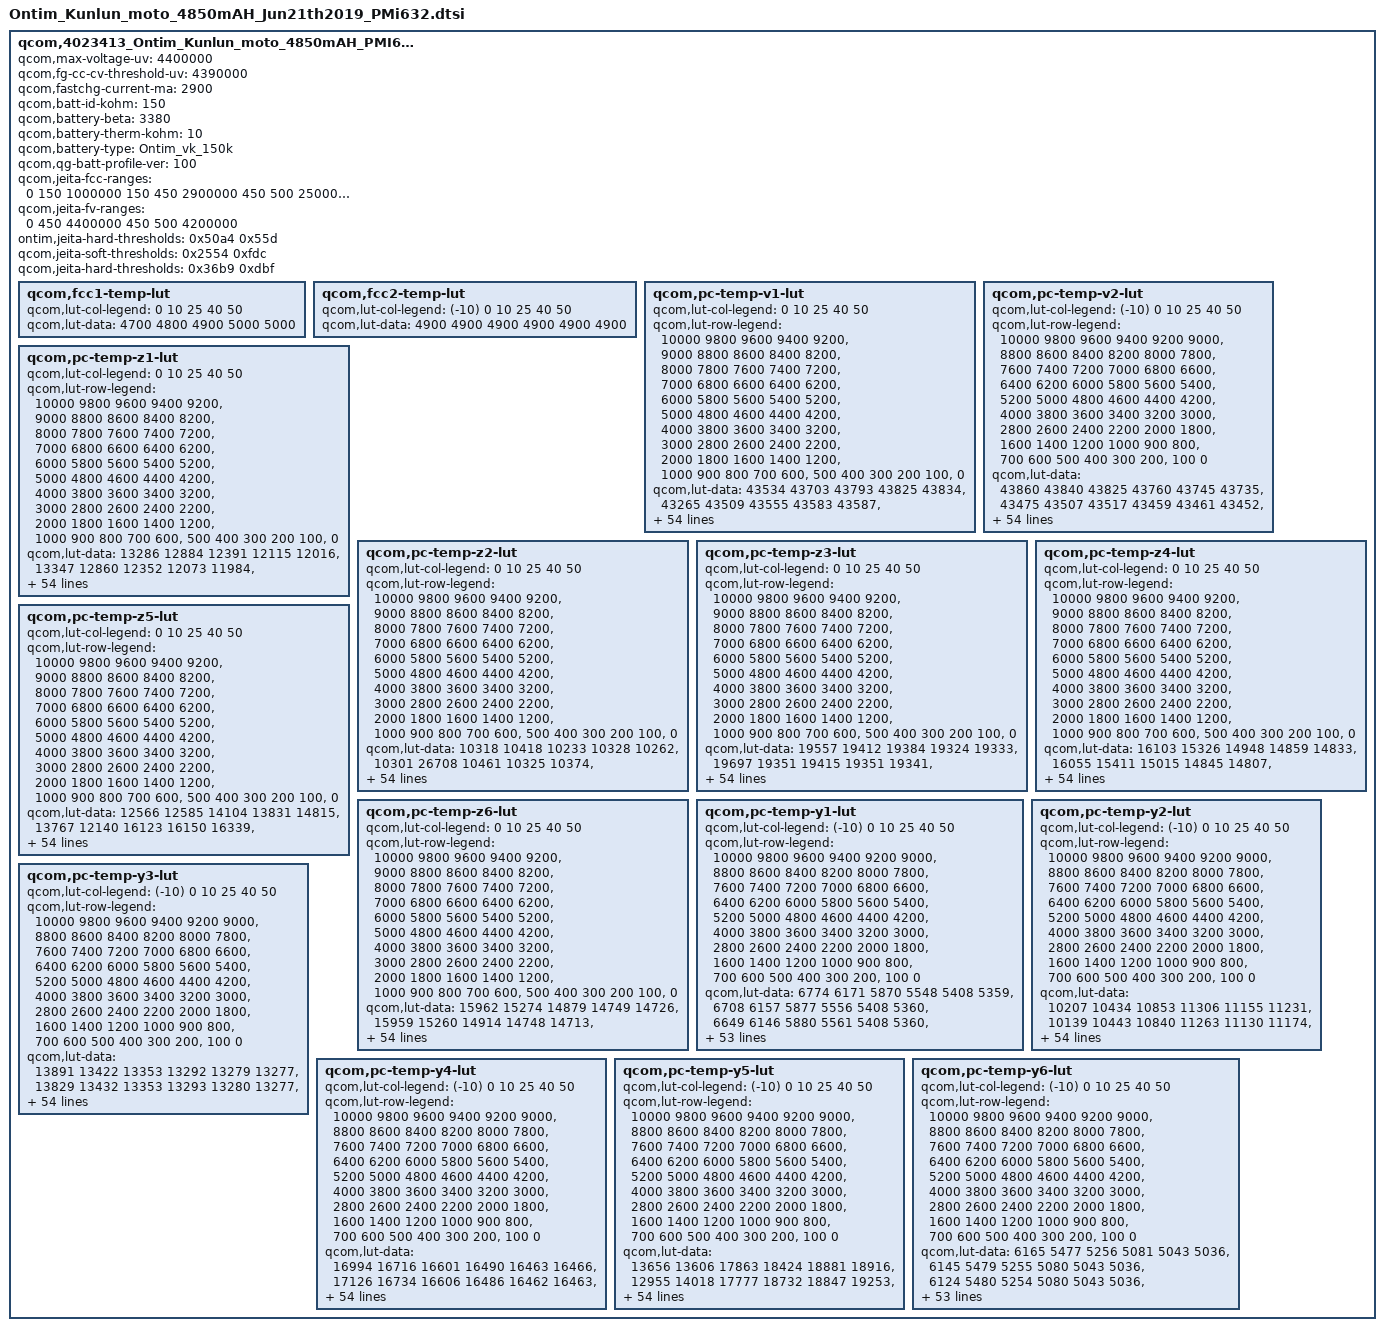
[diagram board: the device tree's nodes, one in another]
qcom,4023413_Ontim_Kunlun_moto_4850mAH_PMI632 {
    /* 4023413_Ontim_Kunlun_moto_4850mAH_PMI632_averaged_MasterSlave_Jun21th2019 */
    qcom,max-voltage-uv = <4400000>;
    qcom,fg-cc-cv-threshold-uv = <4390000>;
    qcom,fastchg-current-ma = <2900>;
    qcom,batt-id-kohm = <150>;
    qcom,battery-beta = <3380>;
    qcom,battery-therm-kohm = <10>;
    qcom,battery-type = "Ontim_vk_150k";
    qcom,qg-batt-profile-ver = <100>;

	qcom,jeita-fcc-ranges = <0     150   1000000
							 150   450   2900000
							 450   500   2500000>;
	
	qcom,jeita-fv-ranges = <0    450   4400000
							450  500   4200000>;

	/* ontim config jeita for dual 85 test begin */
	/* COLD = -20 DegC, HOT = 85 DegC */
	ontim,jeita-hard-thresholds = <0x50a4 0x55d>;
	/* ontim config jeita for dual 85 test end */

	/* COOL = 15 DegC, WARM = 45 DegC */
	qcom,jeita-soft-thresholds = <0x2554 0xfdc>;
	/* COLD = 0 DegC, HOT = 50 DegC */
	qcom,jeita-hard-thresholds = <0x36b9 0xdbf>;

	qcom,fcc1-temp-lut {
		qcom,lut-col-legend = <0 10 25 40 50>;
		qcom,lut-data = <4700 4800 4900 5000 5000>;
	};

	qcom,fcc2-temp-lut {
		qcom,lut-col-legend = <(-10) 0 10 25 40 50>;
		qcom,lut-data = <4900 4900 4900 4900 4900 4900>;
	};

	qcom,pc-temp-v1-lut {
		qcom,lut-col-legend = <0 10 25 40 50>;
		qcom,lut-row-legend = <10000 9800 9600 9400 9200>,
			<9000 8800 8600 8400 8200>,
			<8000 7800 7600 7400 7200>,
			<7000 6800 6600 6400 6200>,
			<6000 5800 5600 5400 5200>,
			<5000 4800 4600 4400 4200>,
			<4000 3800 3600 3400 3200>,
			<3000 2800 2600 2400 2200>,
			<2000 1800 1600 1400 1200>,
			<1000 900 800 700 600>,
			<500 400 300 200 100>,
			<0>;
		qcom,lut-data = <43534 43703 43793 43825 43834>,
			<43265 43509 43555 43583 43587>,
			<43012 43229 43315 43356 43359>,
			<42776 42958 43073 43120 43127>,
			<42547 42720 42833 42882 42894>,
			<42320 42489 42596 42648 42664>,
			<42095 42259 42362 42416 42434>,
			<41877 42032 42130 42185 42203>,
			<41661 41810 41901 41956 41971>,
			<41453 41589 41678 41729 41742>,
			<41264 41375 41459 41504 41520>,
			<41091 41181 41246 41285 41304>,
			<40898 41002 41043 41075 41090>,
			<40654 40804 40847 40874 40881>,
			<40402 40570 40641 40672 40676>,
			<40197 40339 40427 40461 40477>,
			<40021 40148 40228 40260 40285>,
			<39862 39979 40056 40087 40109>,
			<39719 39826 39896 39928 39943>,
			<39587 39695 39744 39769 39779>,
			<39459 39564 39603 39613 39621>,
			<39337 39409 39427 39439 39449>,
			<39216 39239 39152 39202 39222>,
			<39093 39056 38894 38954 38976>,
			<38970 38833 38760 38801 38817>,
			<38840 38648 38668 38697 38711>,
			<38694 38551 38584 38604 38615>,
			<38565 38483 38506 38511 38511>,
			<38467 38426 38434 38423 38414>,
			<38385 38377 38366 38341 38327>,
			<38328 38333 38303 38263 38248>,
			<38287 38289 38244 38194 38177>,
			<38253 38246 38188 38135 38115>,
			<38222 38208 38137 38079 38055>,
			<38194 38176 38094 38027 37995>,
			<38164 38141 38053 37977 37935>,
			<38137 38102 38011 37927 37875>,
			<38103 38060 37969 37877 37818>,
			<38053 38001 37913 37815 37750>,
			<37978 37916 37826 37728 37658>,
			<37887 37813 37720 37622 37549>,
			<37769 37697 37606 37509 37433>,
			<37632 37561 37477 37383 37305>,
			<37471 37402 37322 37229 37150>,
			<37332 37256 37175 37086 37014>,
			<37236 37164 37078 36996 36935>,
			<37204 37135 37053 36966 36907>,
			<37179 37111 37034 36949 36887>,
			<37166 37094 37016 36928 36863>,
			<37108 37040 36957 36854 36775>,
			<36862 36789 36694 36572 36473>,
			<36414 36353 36256 36130 36027>,
			<35848 35786 35679 35552 35450>,
			<35000 35000 35000 35000 35000>, // 2
			<34500 34500 34500 34500 34500>, // 1
			<34000 34000 34000 34000 34000>; // 0
	};

	qcom,pc-temp-v2-lut {
		qcom,lut-col-legend = <(-10) 0 10 25 40 50>;
		qcom,lut-row-legend = <10000 9800 9600 9400 9200 9000>,
			<8800 8600 8400 8200 8000 7800>,
			<7600 7400 7200 7000 6800 6600>,
			<6400 6200 6000 5800 5600 5400>,
			<5200 5000 4800 4600 4400 4200>,
			<4000 3800 3600 3400 3200 3000>,
			<2800 2600 2400 2200 2000 1800>,
			<1600 1400 1200 1000 900 800>,
			<700 600 500 400 300 200>,
			<100 0>;
		qcom,lut-data = <43860 43840 43825 43760 43745 43735>,
			<43475 43507 43517 43459 43461 43452>,
			<43128 43201 43229 43178 43192 43185>,
			<42820 42927 42962 42919 42939 42933>,
			<42544 42681 42714 42680 42700 42697>,
			<42301 42441 42472 42446 42465 42464>,
			<42101 42200 42234 42211 42231 42230>,
			<41908 41964 42000 41979 41999 41998>,
			<41658 41740 41770 41751 41771 41770>,
			<41359 41525 41545 41526 41546 41544>,
			<41152 41315 41327 41306 41323 41322>,
			<41053 41112 41120 41092 41105 41105>,
			<40951 40911 40918 40882 40891 40892>,
			<40673 40721 40719 40679 40691 40687>,
			<40196 40533 40521 40480 40497 40487>,
			<39845 40300 40313 40282 40302 40295>,
			<39612 39973 40094 40080 40104 40110>,
			<39421 39672 39873 39891 39917 39932>,
			<39258 39483 39654 39736 39756 39768>,
			<39115 39331 39438 39590 39603 39606>,
			<38958 39169 39239 39401 39414 39416>,
			<38785 38996 39052 39155 39187 39195>,
			<38622 38836 38883 38933 38978 38989>,
			<38477 38698 38727 38765 38800 38809>,
			<38348 38570 38587 38621 38643 38649>,
			<38252 38438 38465 38497 38516 38519>,
			<38179 38301 38358 38390 38408 38410>,
			<38114 38188 38258 38292 38309 38310>,
			<38053 38099 38166 38201 38218 38218>,
			<37997 38026 38080 38118 38136 38134>,
			<37943 37969 37997 38044 38063 38060>,
			<37891 37921 37921 37976 37996 37991>,
			<37839 37876 37863 37912 37931 37925>,
			<37787 37834 37821 37852 37869 37863>,
			<37734 37793 37783 37794 37804 37795>,
			<37678 37746 37745 37737 37721 37700>,
			<37619 37695 37706 37680 37629 37590>,
			<37554 37640 37660 37616 37541 37489>,
			<37482 37579 37604 37544 37454 37394>,
			<37405 37511 37537 37466 37371 37305>,
			<37327 37433 37452 37384 37296 37229>,
			<37247 37341 37350 37292 37211 37146>,
			<37175 37223 37227 37177 37095 37037>,
			<37105 37091 37088 37050 36968 36907>,
			<37025 36972 36944 36926 36856 36795>,
			<36933 36896 36875 36869 36814 36759>,
			<36885 36864 36839 36853 36800 36745>,
			<36826 36835 36803 36835 36784 36730>,
			<36748 36796 36756 36800 36751 36696>,
			<36594 36714 36653 36706 36637 36557>,
			<36306 36467 36380 36430 36312 36209>,
			<35855 35994 35897 35937 35813 35702>,
			<35218 35354 35250 35308 35164 35049>,
			<35000 35000 35000 35000 35000 35000>, // 2
			<34500 34500 34500 34500 34500 34500>, // 1
			<33000 33000 33000 33000 33000 33000>; // 0
	};

	qcom,pc-temp-z1-lut {
		qcom,lut-col-legend = <0 10 25 40 50>;
		qcom,lut-row-legend = <10000 9800 9600 9400 9200>,
			<9000 8800 8600 8400 8200>,
			<8000 7800 7600 7400 7200>,
			<7000 6800 6600 6400 6200>,
			<6000 5800 5600 5400 5200>,
			<5000 4800 4600 4400 4200>,
			<4000 3800 3600 3400 3200>,
			<3000 2800 2600 2400 2200>,
			<2000 1800 1600 1400 1200>,
			<1000 900 800 700 600>,
			<500 400 300 200 100>,
			<0>;
		qcom,lut-data = <13286 12884 12391 12115 12016>,
			<13347 12860 12352 12073 11984>,
			<13368 12833 12321 12051 11970>,
			<13369 12811 12302 12039 11964>,
			<13367 12799 12288 12031 11958>,
			<13352 12791 12277 12025 11954>,
			<13321 12776 12268 12020 11952>,
			<13301 12752 12259 12017 11951>,
			<13285 12734 12251 12014 11952>,
			<13271 12718 12245 12013 11953>,
			<13269 12708 12240 12015 11955>,
			<13273 12708 12237 12018 11959>,
			<13274 12711 12238 12018 11960>,
			<13263 12711 12238 12018 11961>,
			<13247 12688 12238 12017 11961>,
			<13237 12664 12237 12017 11961>,
			<13229 12661 12236 12016 11962>,
			<13222 12664 12237 12017 11963>,
			<13206 12666 12239 12019 11964>,
			<13190 12666 12242 12021 11966>,
			<13190 12667 12248 12023 11967>,
			<13200 12674 12252 12025 11969>,
			<13208 12686 12255 12027 11970>,
			<13214 12691 12259 12029 11971>,
			<13225 12689 12264 12031 11973>,
			<13229 12688 12270 12034 11975>,
			<13229 12692 12275 12037 11978>,
			<13230 12697 12277 12040 11981>,
			<13241 12700 12280 12043 11984>,
			<13262 12701 12286 12047 11987>,
			<13267 12703 12294 12053 11990>,
			<13251 12710 12302 12057 11994>,
			<13237 12723 12310 12061 11997>,
			<13243 12729 12315 12065 12001>,
			<13259 12733 12318 12070 12005>,
			<13268 12738 12320 12075 12009>,
			<13273 12749 12324 12080 12013>,
			<13278 12766 12331 12084 12016>,
			<13279 12773 12339 12088 12019>,
			<13284 12777 12345 12092 12023>,
			<13291 12780 12351 12096 12026>,
			<13326 12783 12364 12101 12030>,
			<13349 12787 12379 12106 12033>,
			<13342 12808 12379 12111 12036>,
			<13341 12822 12383 12116 12039>,
			<13353 12824 12390 12120 12041>,
			<13336 12802 12390 12120 12041>,
			<13333 12817 12391 12122 12043>,
			<13334 12816 12393 12123 12046>,
			<13363 12832 12401 12128 12050>,
			<13367 12822 12421 12133 12054>,
			<13373 12839 12418 12143 12062>,
			<13396 12888 12428 12152 12072>,
			<13438 12924 12465 12169 12086>,
			<13438 12924 12465 12169 12086>,
			<13438 12924 12465 12169 12086>;
	};

	qcom,pc-temp-z2-lut {
		qcom,lut-col-legend = <0 10 25 40 50>;
		qcom,lut-row-legend = <10000 9800 9600 9400 9200>,
			<9000 8800 8600 8400 8200>,
			<8000 7800 7600 7400 7200>,
			<7000 6800 6600 6400 6200>,
			<6000 5800 5600 5400 5200>,
			<5000 4800 4600 4400 4200>,
			<4000 3800 3600 3400 3200>,
			<3000 2800 2600 2400 2200>,
			<2000 1800 1600 1400 1200>,
			<1000 900 800 700 600>,
			<500 400 300 200 100>,
			<0>;
		qcom,lut-data = <10318 10418 10233 10328 10262>,
			<10301 26708 10461 10325 10374>,
			<10298 15605 10521 10475 10409>,
			<10303 10387 10537 10531 10522>,
			<10309 10357 10538 10552 10600>,
			<10322 10340 10511 10531 10582>,
			<10339 10323 10478 10491 10527>,
			<10346 10307 10462 10478 10511>,
			<10346 10295 10451 10475 10525>,
			<10346 10284 10436 10472 10535>,
			<10342 10276 10415 10466 10465>,
			<10326 10277 10404 10458 10348>,
			<10304 10282 10418 10438 10331>,
			<10255 10288 10447 10391 10352>,
			<10206 10301 10466 10380 10371>,
			<10230 10318 10481 10439 10364>,
			<10350 10336 10487 10492 10347>,
			<10420 10358 10480 10450 10345>,
			<10347 10383 10471 10351 10348>,
			<10242 10417 10483 10332 10356>,
			<10224 10450 10531 10403 10384>,
			<10239 10475 10563 10480 10416>,
			<10255 10497 10580 10534 10440>,
			<10264 10502 10589 10576 10461>,
			<10272 10488 10577 10560 10477>,
			<10284 10476 10546 10469 10490>,
			<10304 10486 10540 10426 10499>,
			<10323 10509 10574 10500 10586>,
			<10338 10517 10605 10589 10697>,
			<10352 10514 10612 10618 10691>,
			<10359 10511 10617 10656 10619>,
			<10362 10515 10618 10653 10544>,
			<10365 10523 10619 10588 10412>,
			<10372 10527 10619 10533 10313>,
			<10384 10529 10618 10522 10320>,
			<10396 10532 10618 10516 10345>,
			<10409 10540 10624 10529 10373>,
			<10422 10553 10647 10586 10422>,
			<10433 10566 10671 10629 10470>,
			<10444 10579 10698 10647 10510>,
			<10458 10590 10720 10657 10544>,
			<10476 10594 10725 10642 10567>,
			<10500 10599 10725 10602 10584>,
			<10531 10616 10728 10613 10612>,
			<10766 10728 10752 10628 10613>,
			<10870 10826 10784 10596 10485>,
			<10878 10826 10779 10573 10501>,
			<10870 10837 10766 10578 10495>,
			<10872 10912 10747 10620 10540>,
			<10885 10967 10814 10700 10566>,
			<10938 10927 10819 10556 10391>,
			<10897 10849 10773 10438 10278>,
			<10646 10819 10696 10383 10220>,
			<10284 10627 10578 10335 10153>,
			<10284 10627 10578 10335 10153>,
			<10284 10627 10578 10335 10153>;
	};

	qcom,pc-temp-z3-lut {
		qcom,lut-col-legend = <0 10 25 40 50>;
		qcom,lut-row-legend = <10000 9800 9600 9400 9200>,
			<9000 8800 8600 8400 8200>,
			<8000 7800 7600 7400 7200>,
			<7000 6800 6600 6400 6200>,
			<6000 5800 5600 5400 5200>,
			<5000 4800 4600 4400 4200>,
			<4000 3800 3600 3400 3200>,
			<3000 2800 2600 2400 2200>,
			<2000 1800 1600 1400 1200>,
			<1000 900 800 700 600>,
			<500 400 300 200 100>,
			<0>;
		qcom,lut-data = <19557 19412 19384 19324 19333>,
			<19697 19351 19415 19351 19341>,
			<19745 19521 19445 19374 19363>,
			<19752 19598 19458 19389 19378>,
			<19755 19598 19461 19396 19386>,
			<19750 19597 19461 19397 19386>,
			<19735 19596 19461 19397 19386>,
			<19726 19594 19460 19397 19386>,
			<19717 19591 19459 19397 19391>,
			<19709 19588 19456 19397 19395>,
			<19702 19583 19449 19395 19390>,
			<19690 19574 19442 19392 19380>,
			<19685 19559 19436 19387 19376>,
			<19700 19551 19432 19382 19374>,
			<19723 19548 19430 19379 19372>,
			<19739 19545 19428 19381 19369>,
			<19752 19538 19427 19382 19365>,
			<19757 19527 19420 19378 19360>,
			<19723 19515 19412 19368 19354>,
			<19671 19501 19410 19363 19350>,
			<19650 19492 19409 19362 19348>,
			<19641 19499 19411 19361 19346>,
			<19637 19517 19419 19362 19347>,
			<19640 19527 19426 19363 19348>,
			<19646 19532 19423 19361 19346>,
			<19653 19535 19413 19348 19332>,
			<19665 19533 19409 19342 19325>,
			<19673 19529 19409 19349 19346>,
			<19671 19525 19408 19360 19376>,
			<19666 19519 19410 19371 19384>,
			<19660 19515 19415 19385 19386>,
			<19651 19513 19420 19390 19383>,
			<19642 19511 19427 19388 19376>,
			<19633 19510 19431 19385 19368>,
			<19624 19506 19429 19380 19361>,
			<19615 19503 19424 19374 19356>,
			<19604 19502 19420 19368 19351>,
			<19595 19501 19415 19364 19348>,
			<19591 19499 19411 19360 19346>,
			<19590 19495 19409 19358 19344>,
			<19587 19491 19408 19356 19343>,
			<19580 19489 19404 19355 19344>,
			<19572 19485 19400 19353 19348>,
			<19564 19480 19399 19355 19353>,
			<19510 19461 19393 19356 19354>,
			<19477 19428 19383 19344 19339>,
			<19468 19424 19377 19342 19332>,
			<19459 19421 19374 19335 19326>,
			<19332 19396 19356 19332 19321>,
			<19329 19393 19346 19328 19324>,
			<19400 19410 19359 19349 19350>,
			<19450 19412 19365 19351 19353>,
			<19388 19348 19375 19353 19352>,
			<19348 19344 19366 19353 19352>,
			<19348 19344 19366 19353 19352>,
			<19348 19344 19366 19353 19352>;
	};

	qcom,pc-temp-z4-lut {
		qcom,lut-col-legend = <0 10 25 40 50>;
		qcom,lut-row-legend = <10000 9800 9600 9400 9200>,
			<9000 8800 8600 8400 8200>,
			<8000 7800 7600 7400 7200>,
			<7000 6800 6600 6400 6200>,
			<6000 5800 5600 5400 5200>,
			<5000 4800 4600 4400 4200>,
			<4000 3800 3600 3400 3200>,
			<3000 2800 2600 2400 2200>,
			<2000 1800 1600 1400 1200>,
			<1000 900 800 700 600>,
			<500 400 300 200 100>,
			<0>;
		qcom,lut-data = <16103 15326 14948 14859 14833>,
			<16055 15411 15015 14845 14807>,
			<15963 15329 15047 14886 14847>,
			<15781 15239 14975 14864 14833>,
			<15588 15144 14916 14836 14811>,
			<15460 15051 14874 14815 14794>,
			<15357 14982 14840 14794 14779>,
			<15271 14926 14810 14776 14763>,
			<15199 14882 14785 14759 14745>,
			<15138 14848 14767 14744 14730>,
			<15084 14821 14753 14729 14722>,
			<15034 14799 14741 14717 14715>,
			<14988 14781 14727 14709 14708>,
			<14950 14769 14715 14704 14701>,
			<14911 14761 14711 14699 14697>,
			<14857 14753 14709 14694 14694>,
			<14782 14745 14706 14689 14691>,
			<14747 14737 14699 14683 14687>,
			<14763 14729 14690 14677 14681>,
			<14786 14720 14682 14675 14679>,
			<14788 14714 14675 14676 14680>,
			<14776 14714 14676 14678 14683>,
			<14763 14715 14746 14725 14721>,
			<14754 14720 14817 14797 14789>,
			<14746 14777 14820 14809 14804>,
			<14745 14827 14818 14809 14805>,
			<14758 14825 14813 14809 14805>,
			<14770 14814 14800 14792 14773>,
			<14777 14802 14782 14765 14727>,
			<14782 14789 14766 14740 14709>,
			<14783 14775 14749 14715 14695>,
			<14777 14762 14733 14699 14687>,
			<14768 14750 14717 14689 14682>,
			<14761 14740 14706 14683 14678>,
			<14753 14730 14699 14682 14678>,
			<14747 14721 14695 14681 14678>,
			<14742 14715 14693 14681 14678>,
			<14737 14709 14692 14681 14678>,
			<14733 14709 14692 14681 14678>,
			<14728 14713 14698 14689 14686>,
			<14726 14717 14705 14699 14697>,
			<14729 14715 14703 14699 14696>,
			<14731 14712 14698 14694 14686>,
			<14725 14709 14696 14691 14685>,
			<14712 14694 14687 14686 14681>,
			<14707 14687 14666 14667 14663>,
			<14709 14683 14662 14662 14661>,
			<14714 14679 14653 14653 14651>,
			<14847 14696 14662 14638 14634>,
			<14844 14692 14669 14641 14630>,
			<14768 14689 14677 14652 14644>,
			<14732 14699 14678 14660 14653>,
			<14817 14775 14672 14662 14658>,
			<14880 14789 14685 14666 14661>,
			<14880 14789 14685 14666 14661>,
			<14880 14789 14685 14666 14661>;
	};

	qcom,pc-temp-z5-lut {
		qcom,lut-col-legend = <0 10 25 40 50>;
		qcom,lut-row-legend = <10000 9800 9600 9400 9200>,
			<9000 8800 8600 8400 8200>,
			<8000 7800 7600 7400 7200>,
			<7000 6800 6600 6400 6200>,
			<6000 5800 5600 5400 5200>,
			<5000 4800 4600 4400 4200>,
			<4000 3800 3600 3400 3200>,
			<3000 2800 2600 2400 2200>,
			<2000 1800 1600 1400 1200>,
			<1000 900 800 700 600>,
			<500 400 300 200 100>,
			<0>;
		qcom,lut-data = <12566 12585 14104 13831 14815>,
			<13767 12140 16123 16150 16339>,
			<14372 14838 17150 17213 17871>,
			<14632 16495 18100 18467 19624>,
			<14818 16921 18821 19402 20833>,
			<15024 17254 19286 19635 20967>,
			<15231 17794 19734 19771 20955>,
			<15372 18487 20442 20049 21244>,
			<15614 19211 21244 20587 23263>,
			<15823 20091 21532 21238 24801>,
			<15867 20795 21488 22104 24353>,
			<16041 20998 21497 22946 23585>,
			<16352 21098 22048 23209 23639>,
			<17539 21400 22994 23068 24652>,
			<19462 23470 23680 23379 25569>,
			<21851 25445 24254 25704 26429>,
			<25179 25192 24626 27756 27104>,
			<26803 24243 24758 27373 27015>,
			<24626 23868 24894 26335 26645>,
			<21460 23849 26055 26408 26618>,
			<21000 23876 30018 29199 27821>,
			<21936 29330 34621 31192 28835>,
			<23360 42640 41863 30689 28169>,
			<25756 48655 47442 29405 26325>,
			<29708 50285 43432 26777 23619>,
			<35348 51028 32415 21128 18782>,
			<45644 48633 26903 18356 16337>,
			<52746 42494 24691 18465 19720>,
			<52690 37967 23704 19045 24364>,
			<51261 34468 23978 21118 26079>,
			<49254 32475 24822 25513 28314>,
			<45001 32385 26519 28292 29093>,
			<40515 32505 30928 30810 29191>,
			<37773 32578 34716 32635 29295>,
			<35590 32764 36924 33325 29886>,
			<33541 33078 38387 33945 31051>,
			<31165 34313 38271 33929 31290>,
			<29548 36266 37019 33065 31135>,
			<29978 36614 35728 31855 30840>,
			<31602 35563 34286 29804 28601>,
			<32316 34595 32523 27269 25614>,
			<31258 33346 30265 25136 25083>,
			<30575 32056 28031 23422 25663>,
			<32014 31252 27632 24454 27956>,
			<29695 31574 27928 25338 29092>,
			<25920 26606 29099 22812 23201>,
			<23873 25534 26586 22794 20476>,
			<22775 24780 26701 21612 20409>,
			<13001 19348 20852 23748 23060>,
			<13160 19696 18782 21267 25440>,
			<18691 22240 19651 22792 27306>,
			<20015 20517 19371 20455 24041>,
			<15055 14009 20349 19717 20804>,
			<12709 13441 17917 18212 18505>,
			<12709 13441 17917 18212 18505>,
			<12709 13441 17917 18212 18505>;
	};

	qcom,pc-temp-z6-lut {
		qcom,lut-col-legend = <0 10 25 40 50>;
		qcom,lut-row-legend = <10000 9800 9600 9400 9200>,
			<9000 8800 8600 8400 8200>,
			<8000 7800 7600 7400 7200>,
			<7000 6800 6600 6400 6200>,
			<6000 5800 5600 5400 5200>,
			<5000 4800 4600 4400 4200>,
			<4000 3800 3600 3400 3200>,
			<3000 2800 2600 2400 2200>,
			<2000 1800 1600 1400 1200>,
			<1000 900 800 700 600>,
			<500 400 300 200 100>,
			<0>;
		qcom,lut-data = <15962 15274 14879 14749 14726>,
			<15959 15260 14914 14748 14713>,
			<15943 15273 14935 14774 14738>,
			<15847 15278 14908 14769 14737>,
			<15727 15232 14882 14762 14734>,
			<15647 15165 14861 14754 14729>,
			<15579 15123 14843 14744 14721>,
			<15522 15088 14828 14735 14715>,
			<15476 15060 14815 14728 14711>,
			<15436 15038 14803 14721 14706>,
			<15398 15019 14793 14714 14700>,
			<15361 14999 14783 14708 14692>,
			<15332 14980 14774 14701 14687>,
			<15310 14965 14767 14696 14683>,
			<15290 14953 14763 14692 14679>,
			<15268 14943 14761 14690 14676>,
			<15244 14934 14758 14689 14673>,
			<15223 14925 14751 14683 14668>,
			<15206 14917 14744 14675 14662>,
			<15191 14908 14740 14673 14659>,
			<15181 14902 14738 14673 14659>,
			<15173 14905 14739 14673 14659>,
			<15169 14915 14774 14693 14675>,
			<15170 14928 14809 14725 14706>,
			<15172 14957 14810 14730 14711>,
			<15177 14979 14806 14726 14706>,
			<15192 14978 14801 14721 14702>,
			<15204 14973 14796 14717 14699>,
			<15206 14967 14790 14713 14697>,
			<15207 14960 14786 14710 14694>,
			<15206 14953 14782 14707 14690>,
			<15202 14948 14779 14704 14685>,
			<15196 14945 14777 14699 14680>,
			<15190 14941 14775 14695 14675>,
			<15185 14937 14772 14692 14671>,
			<15181 14934 14770 14689 14669>,
			<15176 14934 14768 14687 14666>,
			<15173 14933 14766 14684 14664>,
			<15174 14934 14765 14683 14663>,
			<15178 14938 14769 14686 14667>,
			<15182 14941 14772 14690 14671>,
			<15186 14942 14772 14689 14671>,
			<15190 14943 14770 14687 14670>,
			<15192 14944 14770 14688 14672>,
			<15176 14937 14766 14687 14672>,
			<15164 14923 14754 14673 14656>,
			<15159 14919 14750 14670 14652>,
			<15155 14915 14745 14663 14644>,
			<15150 14911 14739 14654 14634>,
			<15153 14914 14739 14655 14634>,
			<15164 14925 14752 14672 14656>,
			<15182 14935 14758 14679 14664>,
			<15200 14943 14765 14683 14668>,
			<15224 14962 14772 14689 14673>,
			<15224 14962 14772 14689 14673>,
			<15224 14962 14772 14689 14673>;
	};

	qcom,pc-temp-y1-lut {
		qcom,lut-col-legend = <(-10) 0 10 25 40 50>;
		qcom,lut-row-legend = <10000 9800 9600 9400 9200 9000>,
			<8800 8600 8400 8200 8000 7800>,
			<7600 7400 7200 7000 6800 6600>,
			<6400 6200 6000 5800 5600 5400>,
			<5200 5000 4800 4600 4400 4200>,
			<4000 3800 3600 3400 3200 3000>,
			<2800 2600 2400 2200 2000 1800>,
			<1600 1400 1200 1000 900 800>,
			<700 600 500 400 300 200>,
			<100 0>;
		qcom,lut-data = <6774 6171 5870 5548 5408 5359>,
			<6708 6157 5877 5556 5408 5360>,
			<6649 6146 5880 5561 5408 5360>,
			<6600 6139 5880 5564 5407 5360>,
			<6569 6135 5877 5565 5406 5360>,
			<6559 6135 5873 5565 5405 5359>,
			<6576 6139 5863 5560 5403 5358>,
			<6597 6144 5852 5555 5401 5358>,
			<6594 6143 5846 5553 5400 5358>,
			<6574 6140 5839 5552 5399 5357>,
			<6564 6141 5837 5551 5398 5357>,
			<6574 6155 5848 5551 5397 5357>,
			<6585 6170 5857 5550 5396 5356>,
			<6587 6173 5855 5550 5396 5356>,
			<6589 6175 5849 5550 5396 5356>,
			<6590 6178 5845 5550 5397 5356>,
			<6588 6180 5843 5551 5398 5357>,
			<6587 6181 5842 5551 5399 5357>,
			<6579 6181 5845 5554 5399 5358>,
			<6565 6180 5851 5558 5400 5358>,
			<6562 6176 5851 5561 5400 5359>,
			<6564 6163 5847 5563 5401 5359>,
			<6565 6155 5844 5565 5403 5360>,
			<6560 6159 5848 5568 5405 5362>,
			<6553 6164 5855 5571 5406 5363>,
			<6557 6168 5854 5576 5409 5365>,
			<6580 6177 5850 5582 5412 5367>,
			<6594 6180 5850 5587 5415 5369>,
			<6592 6175 5862 5591 5418 5372>,
			<6589 6169 5872 5595 5421 5374>,
			<6586 6164 5874 5600 5424 5377>,
			<6577 6160 5873 5607 5428 5379>,
			<6569 6156 5873 5611 5432 5381>,
			<6565 6159 5876 5615 5436 5385>,
			<6563 6163 5879 5619 5439 5387>,
			<6557 6159 5881 5621 5442 5389>,
			<6543 6150 5883 5625 5445 5391>,
			<6537 6149 5885 5627 5446 5392>,
			<6542 6165 5888 5633 5447 5394>,
			<6546 6178 5890 5637 5448 5395>,
			<6541 6175 5900 5636 5450 5396>,
			<6533 6168 5907 5635 5453 5397>,
			<6554 6151 5899 5643 5454 5399>,
			<6572 6153 5896 5646 5458 5402>,
			<6608 6187 5913 5649 5462 5407>,
			<6590 6172 5897 5657 5466 5408>,
			<6622 6186 5906 5670 5467 5408>,
			<6575 6179 5909 5674 5466 5407>,
			<6593 6168 5903 5669 5465 5407>,
			<6568 6179 5904 5673 5465 5408>,
			<6595 6190 5908 5670 5469 5411>,
			<6600 6178 5917 5681 5476 5417>,
			<6626 6198 5927 5699 5484 5424>,
			<6697 6226 5947 5721 5496 5434>,
			<6697 6226 5947 5721 5496 5434>,
			<6697 6226 5947 5721 5496 5434>;
	};

	qcom,pc-temp-y2-lut {
		qcom,lut-col-legend = <(-10) 0 10 25 40 50>;
		qcom,lut-row-legend = <10000 9800 9600 9400 9200 9000>,
			<8800 8600 8400 8200 8000 7800>,
			<7600 7400 7200 7000 6800 6600>,
			<6400 6200 6000 5800 5600 5400>,
			<5200 5000 4800 4600 4400 4200>,
			<4000 3800 3600 3400 3200 3000>,
			<2800 2600 2400 2200 2000 1800>,
			<1600 1400 1200 1000 900 800>,
			<700 600 500 400 300 200>,
			<100 0>;
		qcom,lut-data = <10207 10434 10853 11306 11155 11231>,
			<10139 10443 10840 11263 11130 11174>,
			<10113 10453 10824 11219 11103 11115>,
			<10120 10464 10809 11178 11077 11059>,
			<10149 10476 10797 11144 11053 11013>,
			<10191 10489 10790 11120 11033 10982>,
			<10257 10507 10786 11105 11000 10959>,
			<10345 10522 10784 11092 10967 10946>,
			<10449 10523 10788 11074 10959 10949>,
			<10578 10522 10799 11052 10956 10962>,
			<10628 10529 10808 11045 10951 10966>,
			<10610 10676 10813 11051 10940 10942>,
			<10589 10837 10821 11060 10932 10920>,
			<10532 10872 10890 11072 10955 10916>,
			<10375 10890 11026 11093 11009 10912>,
			<10281 10896 11082 11125 11034 10916>,
			<9969 10904 11098 11183 11045 10941>,
			<9705 10917 11111 11250 11066 10974>,
			<9691 10951 11124 11324 11171 11046>,
			<9686 11012 11139 11392 11311 11143>,
			<9682 11070 11160 11398 11329 11191>,
			<9680 11133 11192 11367 11300 11235>,
			<9678 11175 11224 11347 11266 11253>,
			<9675 11178 11250 11348 11228 11235>,
			<9673 11168 11278 11351 11198 11210>,
			<9671 11159 11316 11367 11201 11196>,
			<9670 11134 11364 11411 11223 11185>,
			<9669 11121 11381 11453 11251 11188>,
			<9668 11114 11378 11483 11295 11238>,
			<9667 11094 11373 11511 11350 11295>,
			<9666 10968 11371 11540 11415 11318>,
			<9666 10612 11368 11569 11486 11336>,
			<9665 10426 11363 11577 11521 11370>,
			<9664 10388 11349 11570 11540 11450>,
			<9664 10354 11331 11560 11548 11504>,
			<9663 10183 11303 11550 11479 11469>,
			<9663 9839 11267 11534 11360 11396>,
			<9662 9714 11230 11513 11329 11339>,
			<9662 9696 11193 11476 11329 11268>,
			<9662 9686 11149 11441 11335 11234>,
			<9661 9681 11087 11420 11374 11254>,
			<9661 9677 11021 11401 11400 11272>,
			<9661 9674 10954 11385 11342 11256>,
			<9660 9671 10845 11356 11269 11171>,
			<9660 9671 10694 11347 11225 11134>,
			<9660 9667 10580 11265 11125 10961>,
			<9659 9666 10244 11255 11096 10921>,
			<9659 9664 9981 11226 11160 10973>,
			<9659 9663 9819 11236 11192 11026>,
			<9658 9662 9775 11229 11168 10975>,
			<9658 9661 9727 11184 11098 10882>,
			<9657 9659 9694 11100 11055 10830>,
			<9655 9658 9677 11027 10961 10757>,
			<9652 9656 9667 10948 10838 10603>,
			<9652 9656 9667 10948 10838 10603>,
			<9652 9656 9667 10948 10838 10603>;
	};

	qcom,pc-temp-y3-lut {
		qcom,lut-col-legend = <(-10) 0 10 25 40 50>;
		qcom,lut-row-legend = <10000 9800 9600 9400 9200 9000>,
			<8800 8600 8400 8200 8000 7800>,
			<7600 7400 7200 7000 6800 6600>,
			<6400 6200 6000 5800 5600 5400>,
			<5200 5000 4800 4600 4400 4200>,
			<4000 3800 3600 3400 3200 3000>,
			<2800 2600 2400 2200 2000 1800>,
			<1600 1400 1200 1000 900 800>,
			<700 600 500 400 300 200>,
			<100 0>;
		qcom,lut-data = <13891 13422 13353 13292 13279 13277>,
			<13829 13432 13353 13293 13280 13277>,
			<13778 13438 13354 13294 13280 13278>,
			<13740 13442 13354 13295 13281 13278>,
			<13716 13444 13354 13296 13281 13279>,
			<13710 13444 13355 13297 13282 13279>,
			<13727 13441 13356 13297 13282 13280>,
			<13749 13437 13357 13298 13283 13280>,
			<13712 13441 13357 13298 13283 13281>,
			<13581 13453 13356 13298 13284 13281>,
			<13519 13458 13356 13299 13284 13282>,
			<13515 13440 13357 13300 13285 13282>,
			<13516 13420 13359 13302 13285 13283>,
			<13513 13415 13356 13302 13287 13283>,
			<13505 13411 13350 13303 13291 13284>,
			<13495 13409 13349 13303 13292 13284>,
			<13466 13404 13349 13303 13290 13286>,
			<13442 13397 13349 13302 13289 13288>,
			<13448 13389 13345 13303 13289 13288>,
			<13461 13380 13339 13305 13290 13288>,
			<13465 13371 13334 13305 13290 13288>,
			<13463 13361 13331 13301 13287 13285>,
			<13460 13353 13327 13297 13284 13282>,
			<13451 13347 13322 13295 13282 13279>,
			<13438 13342 13319 13293 13281 13278>,
			<13439 13340 13317 13292 13280 13278>,
			<13457 13337 13315 13292 13280 13278>,
			<13478 13335 13315 13291 13280 13278>,
			<13496 13331 13314 13291 13279 13277>,
			<13516 13326 13313 13290 13279 13277>,
			<13537 13327 13311 13290 13279 13277>,
			<13559 13332 13309 13291 13279 13277>,
			<13582 13337 13308 13291 13280 13277>,
			<13604 13340 13310 13291 13281 13278>,
			<13627 13344 13312 13291 13281 13279>,
			<13653 13347 13314 13291 13281 13279>,
			<13681 13349 13316 13291 13281 13278>,
			<13712 13353 13317 13291 13280 13278>,
			<13745 13362 13319 13291 13279 13277>,
			<13779 13375 13320 13290 13279 13277>,
			<13810 13389 13321 13291 13281 13279>,
			<13841 13407 13322 13291 13283 13281>,
			<13877 13426 13323 13293 13282 13281>,
			<13923 13447 13325 13293 13280 13280>,
			<13905 13445 13321 13292 13280 13276>,
			<13974 13492 13329 13293 13284 13283>,
			<14017 13518 13328 13296 13286 13285>,
			<14070 13559 13335 13301 13291 13289>,
			<14126 13606 13353 13306 13293 13290>,
			<14201 13650 13374 13308 13292 13287>,
			<14299 13692 13388 13308 13289 13285>,
			<14455 13771 13411 13308 13290 13286>,
			<14708 13925 13468 13314 13294 13291>,
			<15518 14168 13582 13324 13301 13298>,
			<15518 14168 13582 13324 13301 13298>,
			<15518 14168 13582 13324 13301 13298>;
	};

	qcom,pc-temp-y4-lut {
		qcom,lut-col-legend = <(-10) 0 10 25 40 50>;
		qcom,lut-row-legend = <10000 9800 9600 9400 9200 9000>,
			<8800 8600 8400 8200 8000 7800>,
			<7600 7400 7200 7000 6800 6600>,
			<6400 6200 6000 5800 5600 5400>,
			<5200 5000 4800 4600 4400 4200>,
			<4000 3800 3600 3400 3200 3000>,
			<2800 2600 2400 2200 2000 1800>,
			<1600 1400 1200 1000 900 800>,
			<700 600 500 400 300 200>,
			<100 0>;
		qcom,lut-data = <16994 16716 16601 16490 16463 16466>,
			<17126 16734 16606 16486 16462 16463>,
			<17207 16751 16612 16484 16462 16461>,
			<17248 16768 16618 16483 16461 16460>,
			<17263 16782 16623 16483 16461 16460>,
			<17264 16791 16625 16484 16462 16460>,
			<17193 16799 16624 16486 16463 16460>,
			<17104 16804 16623 16489 16465 16461>,
			<17140 16799 16625 16494 16467 16462>,
			<17298 16783 16635 16500 16470 16464>,
			<17404 16778 16644 16506 16474 16466>,
			<17458 16839 16651 16510 16479 16469>,
			<17490 16910 16661 16515 16484 16472>,
			<17378 16936 16701 16527 16487 16477>,
			<17088 16960 16765 16546 16491 16482>,
			<16981 16954 16779 16562 16496 16487>,
			<16992 16823 16760 16577 16506 16492>,
			<17000 16714 16731 16591 16519 16498>,
			<16972 16713 16689 16610 16541 16515>,
			<16918 16716 16638 16627 16565 16534>,
			<16863 16713 16604 16619 16563 16534>,
			<16796 16694 16578 16557 16534 16519>,
			<16750 16672 16561 16506 16504 16501>,
			<16732 16658 16551 16486 16479 16480>,
			<16721 16644 16544 16474 16462 16463>,
			<16716 16618 16542 16473 16460 16460>,
			<16714 16573 16541 16475 16461 16460>,
			<16713 16550 16540 16477 16462 16460>,
			<16711 16549 16535 16482 16467 16464>,
			<16709 16551 16529 16487 16475 16472>,
			<16710 16559 16522 16492 16483 16480>,
			<16713 16573 16515 16498 16492 16489>,
			<16716 16586 16513 16501 16499 16497>,
			<16719 16596 16521 16503 16503 16505>,
			<16723 16606 16531 16504 16506 16509>,
			<16724 16623 16541 16503 16497 16499>,
			<16726 16645 16553 16499 16480 16481>,
			<16726 16657 16563 16495 16472 16471>,
			<16721 16663 16573 16491 16466 16464>,
			<16717 16666 16578 16488 16464 16462>,
			<16718 16664 16579 16492 16470 16470>,
			<16723 16659 16579 16497 16474 16476>,
			<16733 16649 16576 16499 16473 16475>,
			<16744 16636 16570 16497 16466 16461>,
			<16731 16617 16547 16476 16449 16445>,
			<16746 16619 16561 16489 16461 16460>,
			<16758 16634 16590 16504 16479 16488>,
			<16781 16652 16622 16521 16507 16523>,
			<16801 16678 16662 16550 16541 16552>,
			<16807 16704 16695 16569 16536 16530>,
			<16794 16701 16697 16548 16484 16479>,
			<16781 16671 16692 16529 16473 16472>,
			<16787 16673 16710 16547 16479 16474>,
			<17041 16700 16760 16593 16510 16496>,
			<17041 16700 16760 16593 16510 16496>,
			<17041 16700 16760 16593 16510 16496>;
	};

	qcom,pc-temp-y5-lut {
		qcom,lut-col-legend = <(-10) 0 10 25 40 50>;
		qcom,lut-row-legend = <10000 9800 9600 9400 9200 9000>,
			<8800 8600 8400 8200 8000 7800>,
			<7600 7400 7200 7000 6800 6600>,
			<6400 6200 6000 5800 5600 5400>,
			<5200 5000 4800 4600 4400 4200>,
			<4000 3800 3600 3400 3200 3000>,
			<2800 2600 2400 2200 2000 1800>,
			<1600 1400 1200 1000 900 800>,
			<700 600 500 400 300 200>,
			<100 0>;
		qcom,lut-data = <13656 13606 17863 18424 18881 18916>,
			<12955 14018 17777 18732 18847 19253>,
			<12643 14425 17687 18841 18727 19398>,
			<12655 14773 17605 18801 18539 19405>,
			<12923 15012 17540 18655 18302 19325>,
			<13408 15088 17503 18448 18031 19205>,
			<15897 14985 17496 17952 17694 18787>,
			<18678 14859 17489 17280 17322 18218>,
			<17823 15297 17286 16678 16950 17799>,
			<14046 16736 16699 16078 16534 17389>,
			<12499 17265 16274 15745 16110 16994>,
			<14680 15733 15951 15677 15582 16621>,
			<17384 14183 15757 15628 15241 16248>,
			<18384 15456 15842 15244 15503 15785>,
			<18700 18923 16157 14590 16075 15327>,
			<18378 20458 17048 14435 16124 15264>,
			<15798 20297 20556 14801 15363 15568>,
			<13661 19957 22960 15459 14818 15786>,
			<14363 19618 22671 17195 14994 15720>,
			<15976 19006 22193 19905 15467 15617>,
			<16677 18862 22114 21751 16655 16125>,
			<16691 18842 22208 23234 19735 18569>,
			<16376 18830 22235 23872 21375 20068>,
			<14955 19725 21150 23364 21374 20298>,
			<13079 21230 19829 22458 21240 20401>,
			<12755 21771 19797 21759 20892 20283>,
			<12780 21753 20227 21042 20087 19864>,
			<12823 21293 20844 20542 19222 19288>,
			<12991 19172 22263 20168 18115 17960>,
			<13242 16799 23423 19923 17348 16859>,
			<13422 16298 22500 20193 17442 16777>,
			<13571 16187 20272 21090 17842 16753>,
			<13711 16336 19646 21746 18443 16905>,
			<13859 16639 19925 22154 19703 18338>,
			<13984 16842 20263 22458 20961 19954>,
			<14069 16324 20551 22677 21901 21109>,
			<14155 15038 20795 22844 22628 22021>,
			<14167 14554 20807 22719 22338 21885>,
			<14079 14536 20630 21392 20307 20450>,
			<13925 14587 20398 19994 19145 19626>,
			<13565 14685 20043 19097 20504 20827>,
			<13137 14766 19707 18602 21490 22390>,
			<13083 14515 19375 19050 20525 23541>,
			<13237 14037 18904 19156 19309 22371>,
			<13291 13623 17371 20500 19512 17538>,
			<13407 13887 17723 18144 17643 18490>,
			<13653 13576 15347 17565 17638 17225>,
			<13737 13824 14468 18271 18193 17124>,
			<14221 14160 14552 18462 17992 16909>,
			<14332 14549 15175 18628 17487 16320>,
			<14149 14319 14871 19950 18575 17074>,
			<13962 13963 14358 20646 20158 17381>,
			<13848 13959 14413 20740 20422 19225>,
			<12411 14109 14292 22315 24718 24852>,
			<12411 14109 14292 22315 24718 24852>,
			<12411 14109 14292 22315 24718 24852>;
	};

	qcom,pc-temp-y6-lut {
		qcom,lut-col-legend = <(-10) 0 10 25 40 50>;
		qcom,lut-row-legend = <10000 9800 9600 9400 9200 9000>,
			<8800 8600 8400 8200 8000 7800>,
			<7600 7400 7200 7000 6800 6600>,
			<6400 6200 6000 5800 5600 5400>,
			<5200 5000 4800 4600 4400 4200>,
			<4000 3800 3600 3400 3200 3000>,
			<2800 2600 2400 2200 2000 1800>,
			<1600 1400 1200 1000 900 800>,
			<700 600 500 400 300 200>,
			<100 0>;
		qcom,lut-data = <6165 5477 5256 5081 5043 5036>,
			<6145 5479 5255 5080 5043 5036>,
			<6124 5480 5254 5080 5043 5036>,
			<6105 5480 5252 5080 5043 5036>,
			<6089 5479 5250 5081 5043 5037>,
			<6078 5478 5247 5081 5044 5037>,
			<6071 5475 5244 5081 5044 5038>,
			<6065 5471 5241 5082 5045 5038>,
			<6046 5470 5239 5083 5046 5039>,
			<6008 5469 5238 5085 5047 5040>,
			<5994 5469 5238 5087 5049 5041>,
			<6011 5471 5239 5089 5050 5042>,
			<6028 5475 5242 5091 5052 5044>,
			<5998 5480 5249 5095 5054 5045>,
			<5914 5485 5260 5101 5058 5047>,
			<5872 5484 5263 5105 5060 5049>,
			<5856 5450 5258 5109 5062 5051>,
			<5848 5420 5251 5113 5065 5054>,
			<5848 5416 5237 5119 5071 5059>,
			<5847 5415 5219 5125 5079 5065>,
			<5845 5411 5206 5123 5078 5064>,
			<5831 5403 5196 5102 5067 5057>,
			<5821 5397 5190 5085 5057 5050>,
			<5819 5398 5185 5079 5048 5042>,
			<5820 5398 5182 5075 5042 5036>,
			<5826 5398 5182 5074 5041 5036>,
			<5845 5395 5184 5075 5042 5036>,
			<5866 5394 5185 5076 5042 5036>,
			<5883 5402 5186 5078 5043 5037>,
			<5899 5415 5187 5080 5046 5039>,
			<5918 5428 5188 5083 5048 5041>,
			<5939 5445 5189 5086 5052 5044>,
			<5959 5463 5192 5088 5054 5047>,
			<5979 5482 5200 5090 5057 5050>,
			<5999 5503 5210 5091 5058 5052>,
			<6020 5524 5221 5091 5055 5049>,
			<6043 5544 5233 5091 5051 5043>,
			<6067 5566 5244 5091 5048 5041>,
			<6093 5591 5256 5091 5046 5039>,
			<6120 5617 5269 5091 5046 5038>,
			<6146 5644 5284 5093 5049 5042>,
			<6174 5671 5299 5096 5052 5046>,
			<6205 5698 5317 5100 5051 5046>,
			<6246 5728 5336 5101 5048 5040>,
			<6242 5729 5327 5096 5044 5034>,
			<6301 5778 5368 5103 5051 5044>,
			<6341 5810 5392 5111 5058 5054>,
			<6389 5855 5425 5121 5069 5066>,
			<6440 5903 5466 5133 5081 5075>,
			<6505 5950 5506 5140 5078 5067>,
			<6587 5991 5534 5136 5061 5051>,
			<6715 6053 5584 5133 5060 5051>,
			<6942 6189 5686 5150 5066 5056>,
			<7729 6401 5836 5180 5081 5069>,
			<7729 6401 5836 5180 5081 5069>,
			<7729 6401 5836 5180 5081 5069>;
	};

};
